# ATSAMC21N18A register map
Registers are 32-bit, access not given, no defined reset value unless marked. A register's access mark holds for its fields unless they carry their own. Addresses are absolute; registers are grouped by the start of their names; [hi:lo] are bit positions; {n}, {i} and the like mark numbered series.

## DSU
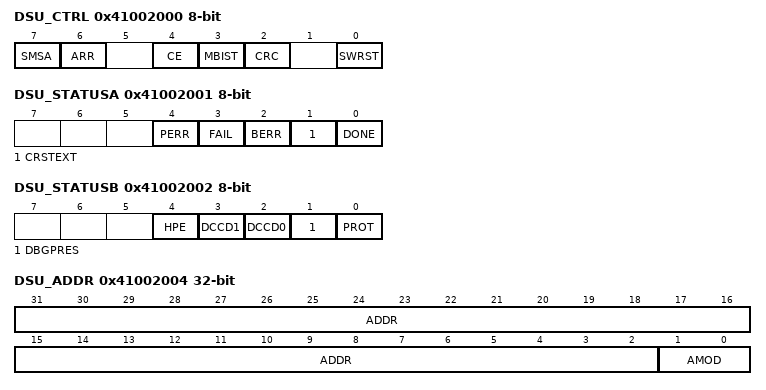
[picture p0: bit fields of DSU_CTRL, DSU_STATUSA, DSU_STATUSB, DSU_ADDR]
0x41002000 DSU_CTRL 8-bit — Control
  [7] SMSA, [6] ARR, [4] CE, [3] MBIST, [2] CRC, [0] SWRST
0x41002001 DSU_STATUSA 8-bit — Status A
  [4] PERR, [3] FAIL, [2] BERR, [1] CRSTEXT, [0] DONE
0x41002002 DSU_STATUSB 8-bit — Status B
  [4] HPE, [3] DCCD1, [2] DCCD0, [1] DBGPRES, [0] PROT
0x41002004 DSU_ADDR — Address
  [31:2] ADDR, [1:0] AMOD
0x41002008 DSU_LENGTH — Length
  [31:2] LENGTH
0x4100200C DSU_DATA — Data
0x41002010 DSU_DCC — Debug Communication Channel n
  [31:0] DATA
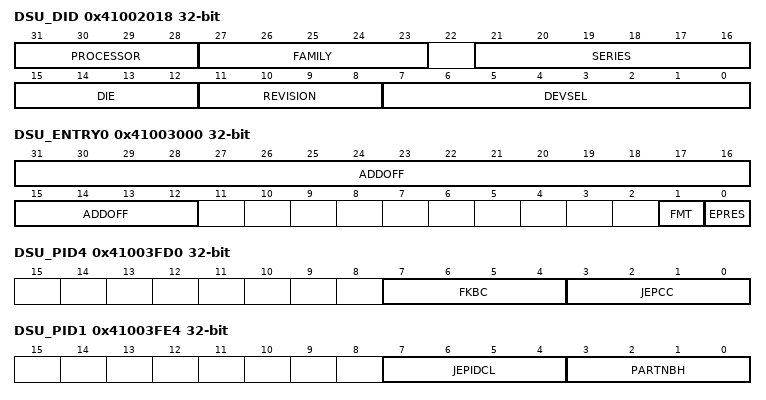
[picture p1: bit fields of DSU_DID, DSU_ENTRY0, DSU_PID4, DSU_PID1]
0x41002018 DSU_DID — Device Identification
  [31:28] PROCESSOR, [27:23] FAMILY, [21:16] SERIES, [15:12] DIE, [11:8] REVISION, [7:0] DEVSEL
0x410020F0 DSU_DCFG — Device Configuration
0x41003000 DSU_ENTRY0 — CoreSight ROM Table Entry 0
  [31:12] ADDOFF, [1] FMT, [0] EPRES
0x41003004 DSU_ENTRY1 — CoreSight ROM Table Entry 1
0x41003008 DSU_END — CoreSight ROM Table End
0x41003FCC DSU_MEMTYPE — CoreSight ROM Table Memory Type
  [0] SMEMP
0x41003FD0 DSU_PID4 — Peripheral Identification 4
  [7:4] FKBC, [3:0] JEPCC
{0x41003FC0+4i} DSU_PID{i} (i=5..7) — Peripheral Identification {i}
0x41003FE0 DSU_PID0 — Peripheral Identification 0
  [7:0] PARTNBL
0x41003FE4 DSU_PID1 — Peripheral Identification 1
  [7:4] JEPIDCL, [3:0] PARTNBH
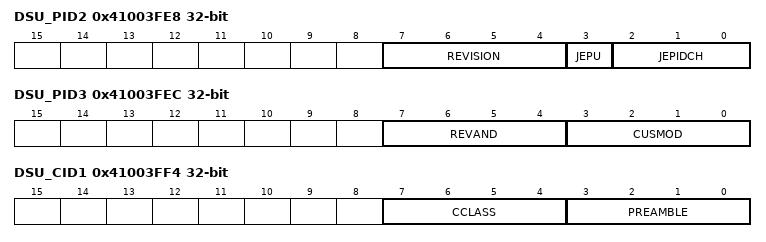
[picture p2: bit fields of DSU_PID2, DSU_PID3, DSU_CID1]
0x41003FE8 DSU_PID2 — Peripheral Identification 2
  [7:4] REVISION, [3] JEPU, [2:0] JEPIDCH
0x41003FEC DSU_PID3 — Peripheral Identification 3
  [7:4] REVAND, [3:0] CUSMOD
0x41003FF0 DSU_CID0 — Component Identification 0
  [7:0] PREAMBLEB0
0x41003FF4 DSU_CID1 — Component Identification 1
  [7:4] CCLASS, [3:0] PREAMBLE
0x41003FF8 DSU_CID2 — Component Identification 2
  [7:0] PREAMBLEB2
0x41003FFC DSU_CID3 — Component Identification 3
  [7:0] PREAMBLEB3

## EIC
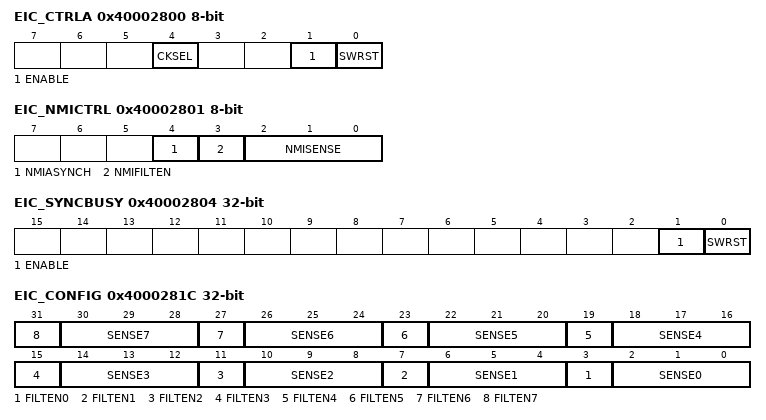
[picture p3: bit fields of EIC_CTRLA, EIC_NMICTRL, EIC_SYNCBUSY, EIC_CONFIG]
0x40002800 EIC_CTRLA 8-bit — Control A
  [4] CKSEL, [1] ENABLE, [0] SWRST
0x40002801 EIC_NMICTRL 8-bit — Non-Maskable Interrupt Control
  [4] NMIASYNCH, [3] NMIFILTEN, [2:0] NMISENSE
0x40002802 EIC_NMIFLAG 16-bit — Non-Maskable Interrupt Flag Status and Clear
  [0] NMI
0x40002804 EIC_SYNCBUSY — Synchronization Busy
  [1] ENABLE, [0] SWRST
0x40002808 EIC_EVCTRL — Event Control
  [15:0] EXTINTEO
0x4000280C EIC_INTENCLR — Interrupt Enable Clear
  [15:0] EXTINT
0x40002810 EIC_INTENSET — Interrupt Enable Set
  [15:0] EXTINT
0x40002814 EIC_INTFLAG — Interrupt Flag Status and Clear
  [15:0] EXTINT
0x40002818 EIC_ASYNCH — External Interrupt Asynchronous Mode
  [15:0] ASYNCH
0x4000281C EIC_CONFIG — External Interrupt Sense Configuration
  [4n+3] FILTEN{n} (n=0..7), [4n+2:4n] SENSE{n} (n=0..7)
0x40002830 EIC_DEBOUNCEN — Debouncer Enable
  [15:0] DEBOUNCEN
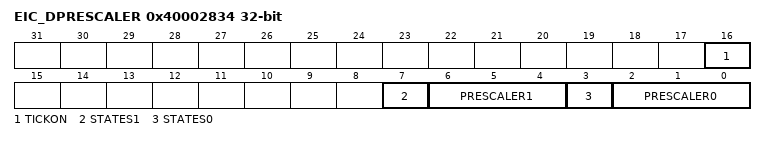
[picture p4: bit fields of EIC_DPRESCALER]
0x40002834 EIC_DPRESCALER — Debouncer Prescaler
  [16] TICKON, [7] STATES1, [6:4] PRESCALER1, [3] STATES0, [2:0] PRESCALER0
0x40002838 EIC_PINSTATE — Pin State
  [15:0] PINSTATE

## EVSYS
0x42000000 EVSYS_CTRLA 8-bit — Control
  [0] SWRST
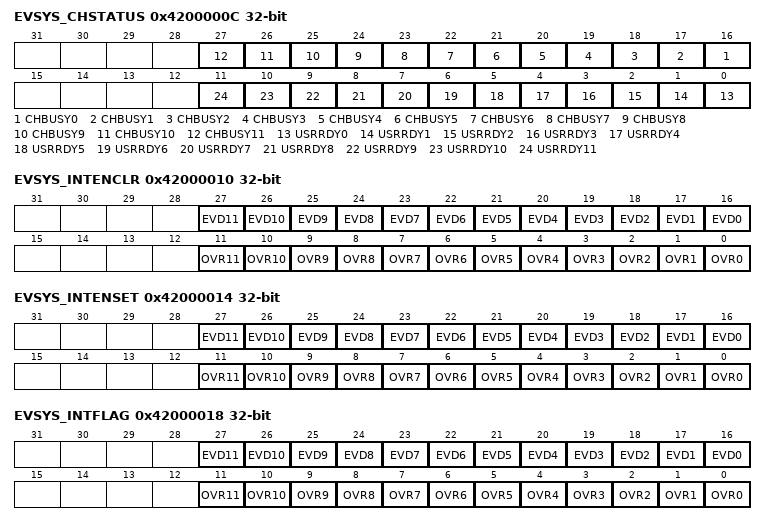
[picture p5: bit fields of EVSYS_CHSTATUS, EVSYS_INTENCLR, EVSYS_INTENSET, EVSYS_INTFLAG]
0x4200000C EVSYS_CHSTATUS — Channel Status
  [n+16] CHBUSY{n} (n=0..11), [n] USRRDY{n} (n=0..11)
0x42000010 EVSYS_INTENCLR — Interrupt Enable Clear
  [n+16] EVD{n} (n=0..11), [n] OVR{n} (n=0..11)
0x42000014 EVSYS_INTENSET — Interrupt Enable Set
  [n+16] EVD{n} (n=0..11), [n] OVR{n} (n=0..11)
0x42000018 EVSYS_INTFLAG — Interrupt Flag Status and Clear
  [n+16] EVD{n} (n=0..11), [n] OVR{n} (n=0..11)
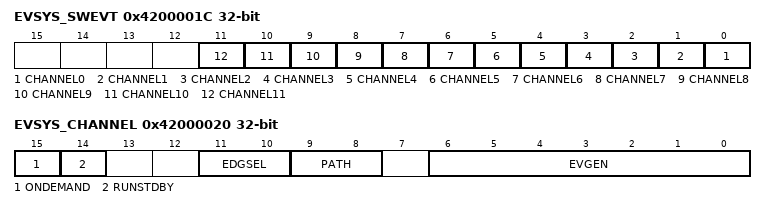
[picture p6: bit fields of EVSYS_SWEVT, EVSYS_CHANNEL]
0x4200001C EVSYS_SWEVT — Software Event
  [n] CHANNEL{n} (n=0..11)
0x42000020 EVSYS_CHANNEL — Channel n
  [15] ONDEMAND, [14] RUNSTDBY, [11:10] EDGSEL, [9:8] PATH, [6:0] EVGEN
0x42000080 EVSYS_USER — User Multiplexer n
  [4:0] CHANNEL

## FREQM
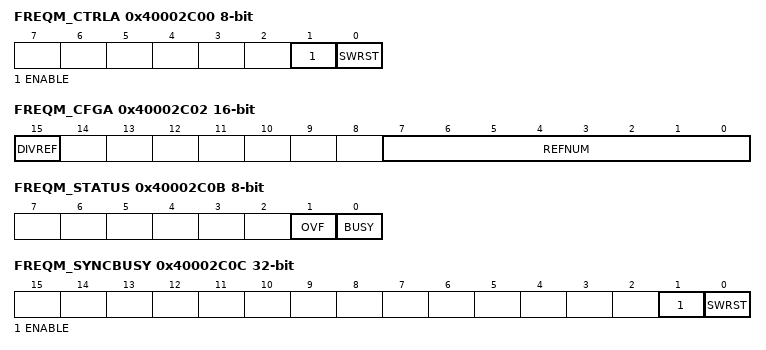
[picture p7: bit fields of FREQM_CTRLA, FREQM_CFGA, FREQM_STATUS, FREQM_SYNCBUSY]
0x40002C00 FREQM_CTRLA 8-bit — Control A Register
  [1] ENABLE, [0] SWRST
0x40002C01 FREQM_CTRLB 8-bit — Control B Register
  [0] START
0x40002C02 FREQM_CFGA 16-bit — Config A register
  [15] DIVREF, [7:0] REFNUM
0x40002C08 FREQM_INTENCLR 8-bit — Interrupt Enable Clear Register
  [0] DONE
0x40002C09 FREQM_INTENSET 8-bit — Interrupt Enable Set Register
  [0] DONE
0x40002C0A FREQM_INTFLAG 8-bit — Interrupt Flag Register
  [0] DONE
0x40002C0B FREQM_STATUS 8-bit — Status Register
  [1] OVF, [0] BUSY
0x40002C0C FREQM_SYNCBUSY — Synchronization Busy Register
  [1] ENABLE, [0] SWRST
0x40002C10 FREQM_VALUE — Count Value Register
  [23:0] VALUE
